# PIC32MZ2048EFM144 register map
Registers are 32-bit, access not given, reset 0x0 unless marked. A register's access mark holds for its fields unless they carry their own. Offsets are from the block's base; [hi:lo] are bit positions; {n}, {i} and the like mark numbered series; 'fields as' and 'values as' point back to an identical list.

## OCMP8 — OCMP8 peripheral
Base 0xBF844E00
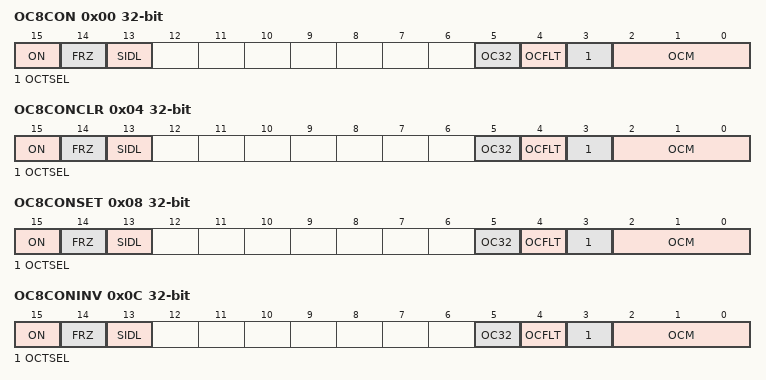
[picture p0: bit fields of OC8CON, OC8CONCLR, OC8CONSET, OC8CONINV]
0x00 OC8CON
  [15] ON, [14] FRZ, [13] SIDL, [5] OC32, [4] OCFLT, [3] OCTSEL, [2:0] OCM
0x04 OC8CONCLR
  fields as OC8CON
0x08 OC8CONSET
  fields as OC8CON
0x0C OC8CONINV
  fields as OC8CON
0x10 OC8R
0x14 OC8RCLR
  [31:0] OC8R
0x18 OC8RSET
  [31:0] OC8R
0x1C OC8RINV
  [31:0] OC8R
0x20 OC8RS
0x24 OC8RSCLR
  [31:0] OC8RS
0x28 OC8RSSET
  [31:0] OC8RS
0x2C OC8RSINV
  [31:0] OC8RS

## OCMP9 — OCMP9 peripheral
Base 0xBF845000
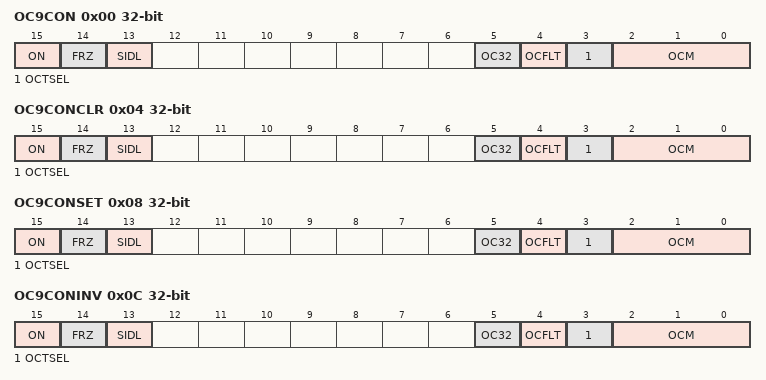
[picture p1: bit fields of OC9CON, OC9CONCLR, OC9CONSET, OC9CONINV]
0x00 OC9CON
  [15] ON, [14] FRZ, [13] SIDL, [5] OC32, [4] OCFLT, [3] OCTSEL, [2:0] OCM
0x04 OC9CONCLR
  fields as OC9CON
0x08 OC9CONSET
  fields as OC9CON
0x0C OC9CONINV
  fields as OC9CON
0x10 OC9R
0x14 OC9RCLR
  [31:0] OC9R
0x18 OC9RSET
  [31:0] OC9R
0x1C OC9RINV
  [31:0] OC9R
0x20 OC9RS
0x24 OC9RSCLR
  [31:0] OC9RS
0x28 OC9RSSET
  [31:0] OC9RS
0x2C OC9RSINV
  [31:0] OC9RS

## ADCHS — ADCHS peripheral
Base 0xBF84B000
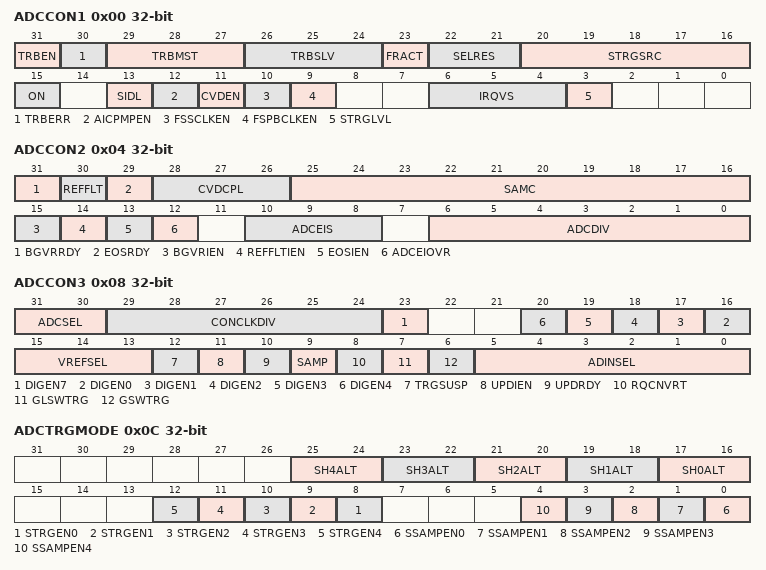
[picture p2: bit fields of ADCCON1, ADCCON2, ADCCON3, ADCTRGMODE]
0x00 ADCCON1
  [31] TRBEN, [30] TRBERR, [29:27] TRBMST, [26:24] TRBSLV, [23] FRACT, [22:21] SELRES, [20:16] STRGSRC, [15] ON, [13] SIDL, [12] AICPMPEN, [11] CVDEN, [10] FSSCLKEN, [9] FSPBCLKEN, [6:4] IRQVS, [3] STRGLVL
0x04 ADCCON2
  [31] BGVRRDY, [30] REFFLT, [29] EOSRDY, [28:26] CVDCPL, [25:16] SAMC, [15] BGVRIEN, [14] REFFLTIEN, [13] EOSIEN, [12] ADCEIOVR, [10:8] ADCEIS, [6:0] ADCDIV
0x08 ADCCON3
  [31:30] ADCSEL, [29:24] CONCLKDIV, [23] DIGEN7, [n+16] DIGEN{n} (n=0..4), [15:13] VREFSEL, [12] TRGSUSP, [11] UPDIEN, [10] UPDRDY, [9] SAMP, [8] RQCNVRT, [7] GLSWTRG, [6] GSWTRG, [5:0] ADINSEL
0x0C ADCTRGMODE
  [2n+17:2n+16] SH{n}ALT (n=0..4), [n+8] STRGEN{n} (n=0..4), [n] SSAMPEN{n} (n=0..4)
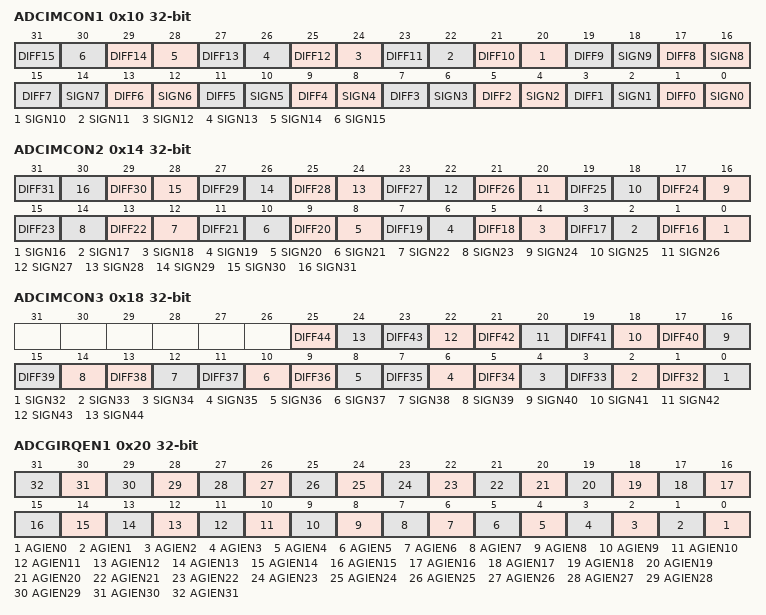
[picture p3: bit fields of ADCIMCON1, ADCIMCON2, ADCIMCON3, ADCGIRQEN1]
0x10 ADCIMCON1
  [2n+1] DIFF{n} (n=0..15), [2n] SIGN{n} (n=0..15)
0x14 ADCIMCON2
  [2n-31] DIFF{n} (n=16..31), [2n-32] SIGN{n} (n=16..31)
0x18 ADCIMCON3
  [2n-63] DIFF{n} (n=32..44), [2n-64] SIGN{n} (n=32..44)
0x20 ADCGIRQEN1
  [n] AGIEN{n} (n=0..31)
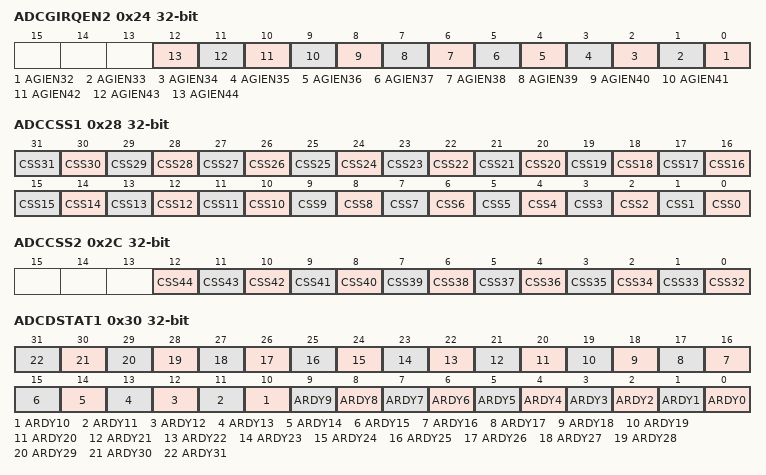
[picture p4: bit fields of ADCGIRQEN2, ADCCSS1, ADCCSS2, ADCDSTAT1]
0x24 ADCGIRQEN2
  [n-32] AGIEN{n} (n=32..44)
0x28 ADCCSS1
  [n] CSS{n} (n=0..31)
0x2C ADCCSS2
  [n-32] CSS{n} (n=32..44)
0x30 ADCDSTAT1
  [n] ARDY{n} (n=0..31)
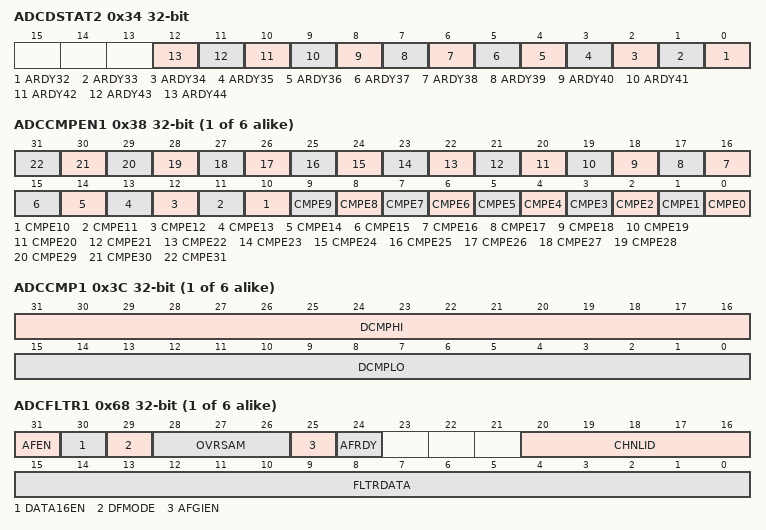
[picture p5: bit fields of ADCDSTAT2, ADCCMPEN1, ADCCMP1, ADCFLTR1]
0x34 ADCDSTAT2
  [n-32] ARDY{n} (n=32..44)
{0x30+8i} ADCCMPEN{i} (i=1..6)
  [n] CMPE{n} (n=0..31)
{0x34+8i} ADCCMP{i} (i=1..6)
  [31:16] DCMPHI, [15:0] DCMPLO
{0x64+4i} ADCFLTR{i} (i=1..6)
  [31] AFEN, [30] DATA16EN, [29] DFMODE, [28:26] OVRSAM, [25] AFGIEN, [24] AFRDY, [20:16] CHNLID, [15:0] FLTRDATA
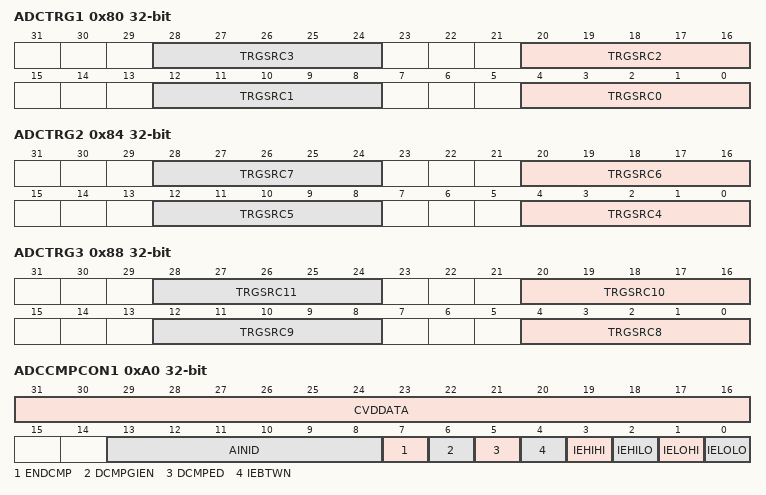
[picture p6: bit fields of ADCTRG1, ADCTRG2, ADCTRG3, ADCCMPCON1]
0x80 ADCTRG1
  [8n+4:8n] TRGSRC{n} (n=0..3)
0x84 ADCTRG2
  [8n-28:8n-32] TRGSRC{n} (n=4..7)
0x88 ADCTRG3
  [8n-60:8n-64] TRGSRC{n} (n=8..11)
0xA0 ADCCMPCON1
  [31:16] CVDDATA, [13:8] AINID, [7] ENDCMP, [6] DCMPGIEN, [5] DCMPED, [4] IEBTWN, [3] IEHIHI, [2] IEHILO, [1] IELOHI, [0] IELOLO
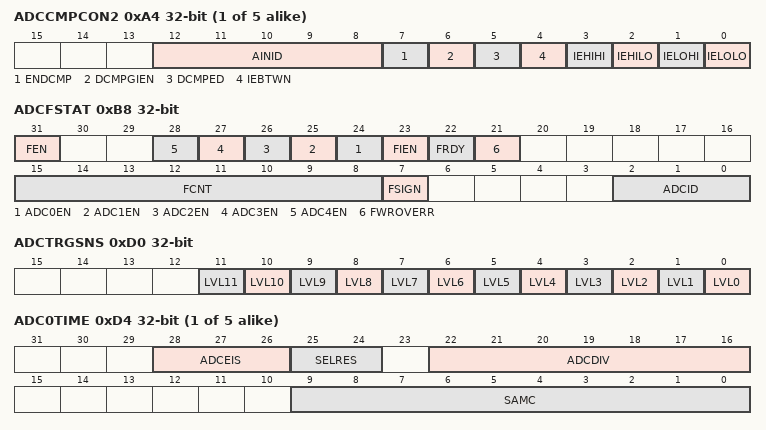
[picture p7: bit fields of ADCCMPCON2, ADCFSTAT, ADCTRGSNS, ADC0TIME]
{0x9C+4i} ADCCMPCON{i} (i=2..6)
  [12:8] AINID, [7] ENDCMP, [6] DCMPGIEN, [5] DCMPED, [4] IEBTWN, [3] IEHIHI, [2] IEHILO, [1] IELOHI, [0] IELOLO
0xB8 ADCFSTAT
  [31] FEN, [n+24] ADC{n}EN (n=0..4), [23] FIEN, [22] FRDY, [21] FWROVERR, [15:8] FCNT, [7] FSIGN, [2:0] ADCID
0xBC ADCFIFO
  [31:0] DATA
0xC0 ADCBASE
  [15:0] ADCBASE
0xD0 ADCTRGSNS
  [n] LVL{n} (n=0..11)
{0xD4+4i} ADC{i}TIME (i=0..4)
  [28:26] ADCEIS, [25:24] SELRES, [22:16] ADCDIV, [9:0] SAMC
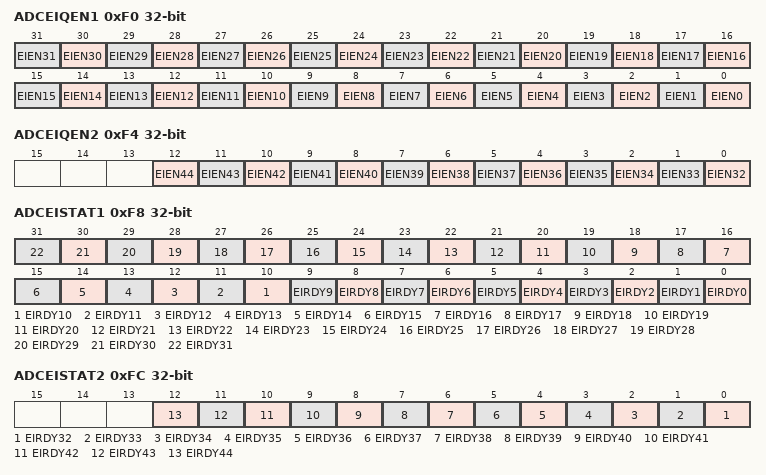
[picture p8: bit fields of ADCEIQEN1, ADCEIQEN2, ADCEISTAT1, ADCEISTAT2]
0xF0 ADCEIQEN1
  [n] EIEN{n} (n=0..31)
0xF4 ADCEIQEN2
  [n-32] EIEN{n} (n=32..44)
0xF8 ADCEISTAT1
  [n] EIRDY{n} (n=0..31)
0xFC ADCEISTAT2
  [n-32] EIRDY{n} (n=32..44)
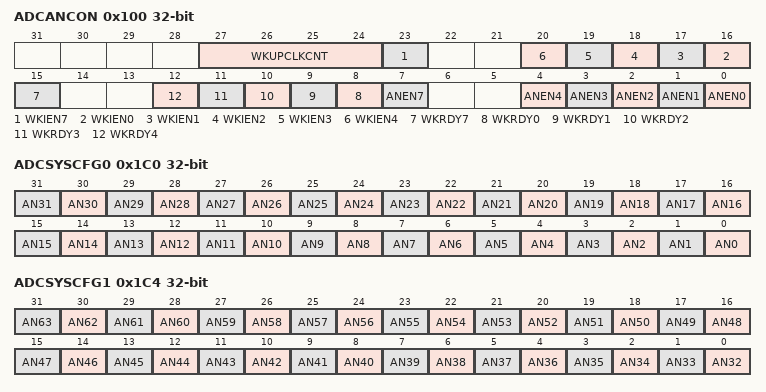
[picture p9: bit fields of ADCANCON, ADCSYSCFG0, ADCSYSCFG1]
0x100 ADCANCON
  [27:24] WKUPCLKCNT, [23] WKIEN7, [n+16] WKIEN{n} (n=0..4), [15] WKRDY7, [n+8] WKRDY{n} (n=0..4), [7] ANEN7, [n] ANEN{n} (n=0..4)
{0x180+4i} ADC{i}CFG (i=0..4)
  [31:0] ADCCFG
0x19C ADC7CFG
  [31:0] ADCCFG
0x1C0 ADCSYSCFG0
  [n] AN{n} (n=0..31)
0x1C4 ADCSYSCFG1
  [n-32] AN{n} (n=32..63)
{0x200+4i} ADCDATA{i} (i=0..44)
  [31:0] DATA

## CMP1 — CMP1 peripheral
Base 0xBF84C000
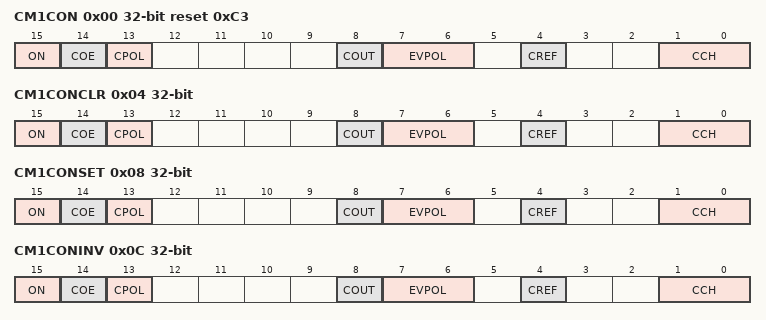
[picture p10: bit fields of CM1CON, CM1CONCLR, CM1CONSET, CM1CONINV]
0x00 CM1CON reset 0xC3
  [15] ON, [14] COE, [13] CPOL, [8] COUT, [7:6] EVPOL, [4] CREF, [1:0] CCH
0x04 CM1CONCLR
  fields as CM1CON
0x08 CM1CONSET
  fields as CM1CON
0x0C CM1CONINV
  fields as CM1CON
